# STM32G474 register map
File version: 2.9
CPU: CM4 r0p1, little endian, MPU, FPU, 4 interrupt priority bits
Registers are 32-bit, read-write, reset 0x0 unless marked. A register's access mark holds for its fields unless they carry their own. Offsets are from the block's base; [hi:lo] are bit positions; {n}, {i} and the like mark numbered series; 'fields as' and 'values as' point back to an identical list.

## HRTIM_TIMA — High Resolution Timer: TIMA
Base 0x40016880
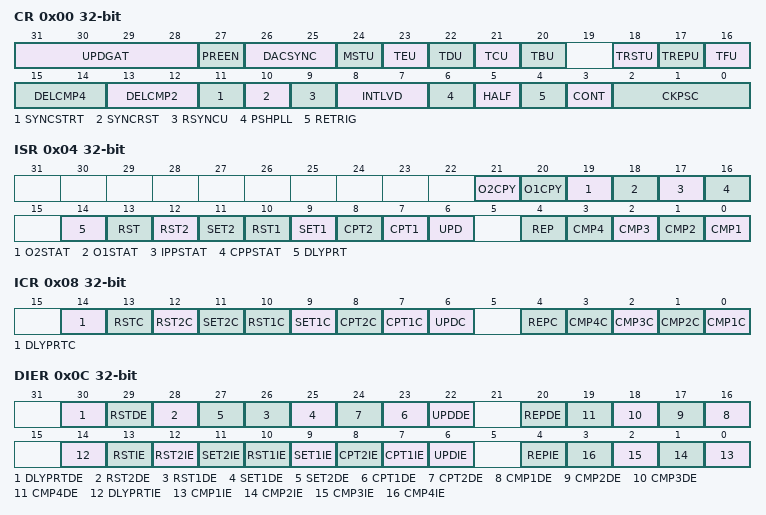
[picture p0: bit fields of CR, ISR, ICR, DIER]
0x00 CR — Timerx Control Register
  [31:28] UPDGAT — Update Gating
    0=Independent (Update occurs independently from the DMA burst transfer); 1=DMABurst (Update occurs when the DMA burst transfer is completed); 2=DMABurst_Update (Update occurs on the update event following DMA burst transfer completion); 3=Input1 (Update occurs on a rising edge of HRTIM update enable input 1); 4=Input2 (Update occurs on a rising edge of HRTIM update enable input 2); 5=Input3 (Update occurs on a rising edge of HRTIM update enable input 3); 6=Input1_Update (Update occurs on the update event following a rising edge of HRTIM update enable input 1); 7=Input2_Update (Update occurs on the update event following a rising edge of HRTIM update enable input 2); 8=Input3_Update (Update occurs on the update event following a rising edge of HRTIM update enable input 3)
  [27] PREEN — Preload enable
    0=Disabled (Preload disabled: the write access is directly done into the active register); 1=Enabled (Preload enabled: the write access is done into the preload register)
  [26:25] DACSYNC — AC Synchronization
    0=Disabled (No DAC trigger generated); 1=Trigger generated on DACSync1; 2=Trigger generated on DACSync2; 3=Trigger generated on DACSync3
  [24] MSTU — Master Timer update
    0=Disabled (Update by master timer disabled); 1=Enabled (Update by master timer enabled)
  [23] TEU
    0=Disabled (Update by timer x disabled); 1=Enabled (Update by timer x enabled)
  [22] TDU
    values as TEU
  [21] TCU
    values as TEU
  [20] TBU
    values as TEU
  [18] TRSTU — Timerx reset update
    0=Disabled (Update by timer x reset/roll-over disabled); 1=Enabled (Update by timer x reset/roll-over enabled)
  [17] TREPU — Timer x Repetition update
    0=Disabled (Update by timer x repetition disabled); 1=Enabled (Update by timer x repetition enabled)
  [16] TFU
    values as TEU
  [15:14] DELCMP4 — Delayed CMP4 mode
    0=Standard (CMP4 register is always active (standard compare mode)); 1=Capture2 (CMP4 is recomputed and is active following a capture 2 event); 2=Capture2_Compare1 (CMP4 is recomputed and is active following a capture 2 event or a Compare 1 match); 3=Capture_Compare3 (CMP4 is recomputed and is active following a capture event or a Compare 3 match)
  [13:12] DELCMP2 — Delayed CMP2 mode
    0=Standard (CMP2 register is always active (standard compare mode)); 1=Capture1 (CMP2 is recomputed and is active following a capture 1 event); 2=Capture1_Compare1 (CMP2 is recomputed and is active following a capture 1 event or a Compare 1 match); 3=Capture1_Compare3 (CMP2 is recomputed and is active following a capture 1 event or a Compare 3 match)
  [11] SYNCSTRT — Synchronization Starts Timer x
    0=Disabled (No effect on the master timer); 1=Start (A synchroniation input event starts the master timer)
  [10] SYNCRST — Synchronization Resets Timer x
    0=Disabled (No effect on the master timer); 1=Reset (A synchroniation input event resets the master timer)
  [9] RSYNCU — Re-Synchronized Update
  [8:7] INTLVD — Interleaved mode
  [6] PSHPLL — Push-Pull mode enable
    0=Disabled (Push-pull mode disabled); 1=Enabled (Push-pull mode enabled)
  [5] HALF — Half mode enable
    0=Disabled (Half mode disabled); 1=Enabled (Half mode enabled)
  [4] RETRIG — Re-triggerable mode
    0=Disabled (The timer is not re-triggerable: a counter reset can be done only if the counter is stopped); 1=Enabled (The timer is retriggerable: a counter reset is done whatever the counter state)
  [3] CONT — Continuous mode
    0=SingleShot (The timer operates in single-shot mode and stops when it reaches the MPER value); 1=Continuous (The timer operates in continuous (free-running) mode and rolls over to zero when it reaches the MPER value)
  [2:0] CKPSC — HRTIM Timer x Clock prescaler
0x04 ISR ro — Timerx Interrupt Status Register
  [21] O2CPY — Output 2 Copy
    0=Inactive (Output is inactive); 1=Active (Output is active)
  [20] O1CPY — Output 1 Copy
    0=Inactive (Output is inactive); 1=Active (Output is active)
  [19] O2STAT — Output 2 State
    0=Inactive (Output was inactive); 1=Active (Output was active)
  [18] O1STAT — Output 1 State
    values as O2STAT
  [17] IPPSTAT — Idle Push Pull Status
    0=Output1Active (Protection occurred when the output 1 was active and output 2 forced inactive); 1=Output2Active (Protection occurred when the output 2 was active and output 1 forced inactive)
  [16] CPPSTAT — Current Push Pull Status
    0=Output1Active (Signal applied on output 1 and output 2 forced inactive); 1=Output2Active (Signal applied on output 2 and output 1 forced inactive)
  [14] DLYPRT — Delayed Protection Flag
    0=Inactive (Not in delayed idle or balanced idle mode); 1=Active (Delayed idle or balanced idle mode entry)
  [13] RST — Reset Interrupt Flag
    0=NoEvent (No TIMx counter reset/roll-over interrupt occurred); 1=Event (TIMx counter reset/roll-over interrupt occurred)
  [12] RST2 — Output 2 Reset Interrupt Flag
    0=NoEvent (No Tx output reset interrupt occurred); 1=Event (Tx output reset interrupt occurred)
  [10] RST1 — Output 1 Reset Interrupt Flag
    values as RST2
  [2n+7] SET{n} (n=1..2) — Output {n} Set Interrupt Flag
    0=NoEvent (No Tx output set interrupt occurred); 1=Event (Tx output set interrupt occurred)
  [n+6] CPT{n} (n=1..2) — Capture{n} Interrupt Flag
    0=NoEvent (No timer x capture reset interrupt occurred); 1=Event (Timer x capture reset interrupt occurred)
  [6] UPD — Update Interrupt Flag
    0=NoEvent (No timer update interrupt occurred); 1=Event (Timer update interrupt occurred)
  [4] REP — Repetition Interrupt Flag
    0=NoEvent (No timer repetition interrupt occurred); 1=Event (Timer repetition interrupt occurred)
  [n-1] CMP{n} (n=1..4) — Compare {n} Interrupt Flag
    0=NoEvent (No compare interrupt occurred); 1=Event (Compare interrupt occurred)
0x08 ICR wo — Timerx Interrupt Clear Register
  [all] fields
    1=Clears associated flag in ISR register
  [14] DLYPRTC write-1-clears — Delayed Protection Flag Clear
  [13] RSTC write-1-clears — Reset Interrupt flag Clear
  [12] RST2C write-1-clears — Output 2 Reset flag Clear
  [10] RST1C write-1-clears — Output 1 Reset flag Clear
  [2n+7] SET{n}C (n=1..2) write-1-clears — Output {n} Set flag Clear
  [n+6] CPT{n}C (n=1..2) write-1-clears — Capture{n} Interrupt flag Clear
  [6] UPDC write-1-clears — Update Interrupt flag Clear
  [4] REPC write-1-clears — Repetition Interrupt flag Clear
  [n-1] CMP{n}C (n=1..4) write-1-clears — Compare {n} Interrupt flag Clear
0x0C DIER — TIMxDIER
  [30] DLYPRTDE
    0=Disabled (DMA request disabled); 1=Enabled (DMA request enabled)
  [29] RSTDE
    values as DLYPRTDE
  [28] RST2DE — RSTx2DE
    values as DLYPRTDE
  [26] RST1DE — RSTx1DE
    values as DLYPRTDE
  [2n+23] SET{n}DE (n=1..2) — Output {n} set DMA request enable
    values as DLYPRTDE
  [n+22] CPT{n}DE (n=1..2) — CPT{n}DE
    values as DLYPRTDE
  [22] UPDDE
    values as DLYPRTDE
  [20] REPDE
    values as DLYPRTDE
  [n+15] CMP{n}DE (n=1..4) — CMP{n}DE
    values as DLYPRTDE
  [14] DLYPRTIE
    0=Disabled (Interrupt disabled); 1=Enabled (Interrupt enabled)
  [13] RSTIE
    values as DLYPRTIE
  [12] RST2IE — RSTx2IE
    values as DLYPRTIE
  [10] RST1IE — RSTx1IE
    values as DLYPRTIE
  [2n+7] SET{n}IE (n=1..2) — Output {n} set interrupt enable
    values as DLYPRTIE
  [n+6] CPT{n}IE (n=1..2) — CPT{n}IE
    values as DLYPRTIE
  [6] UPDIE
    values as DLYPRTIE
  [4] REPIE
    values as DLYPRTIE
  [n-1] CMP{n}IE (n=1..4) — CMP{n}IE
    values as DLYPRTIE
0x10 CNTR — Timerx Counter Register
  [15:0] CNT — Counter value
0x14 PERR reset 0xFFFF — Timerx Period Register
  [15:0] PER — Master Timer Period value
0x18 REPR — Timerx Repetition Register
  [7:0] REP — Master Timer Repetition counter value
0x1C CMP1R — Timerx Compare 1 Register
  [15:0] CMP — Master Timer Compare 1 value
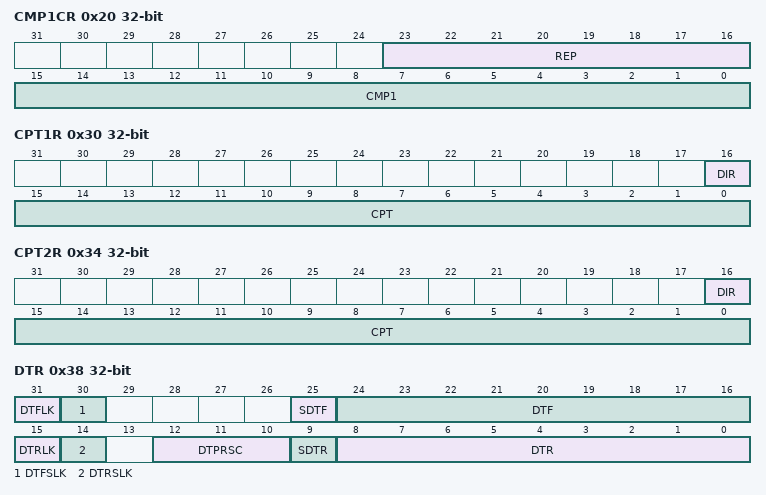
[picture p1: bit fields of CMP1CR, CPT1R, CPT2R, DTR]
0x20 CMP1CR — Timerx Compare 1 Compound Register
  [23:16] REP — Timerx Repetition value (aliased from HRTIM_REPx register)
  [15:0] CMP1 — Timerx Compare 1 value
{0x1C+4i} CMP{i}R (i=2..4) — Timerx Compare {i} Register
  [15:0] CMP — Master Timer Compare 1 value
0x30 CPT1R ro — Timerx Capture 1 Register
  [16] DIR — Timerx Capture 1 Direction status
  [15:0] CPT — Timerx Capture 1 value
0x34 CPT2R ro — Timerx Capture 2 Register
  fields as CPT1R
0x38 DTR — Timerx Deadtime Register
  [31] DTFLK — Deadtime Falling Lock
    0=Unlocked (Deadtime falling value and sign is writable); 1=Locked (Deadtime falling value and sign is read-only)
  [30] DTFSLK — Deadtime Falling Sign Lock
    0=Unlocked (Deadtime falling sign is writable); 1=Locked (Deadtime falling sign is read-only)
  [25] SDTF — Sign Deadtime Falling value
    0=Positive deadtime on falling edge; 1=Negative deadtime on falling edge
  [24:16] DTF — Deadtime Falling value
  [15] DTRLK — Deadtime Rising Lock
    0=Unlocked (Deadtime rising value and sign is writable); 1=Locked (Deadtime rising value and sign is read-only)
  [14] DTRSLK — Deadtime Rising Sign Lock
    0=Unlocked (Deadtime rising sign is writable); 1=Locked (Deadtime rising sign is read-only)
  [12:10] DTPRSC — Deadtime Prescaler
  [9] SDTR — Sign Deadtime Rising value
    0=Positive deadtime on rising edge; 1=Negative deadtime on rising edge
  [8:0] DTR — Deadtime Rising value
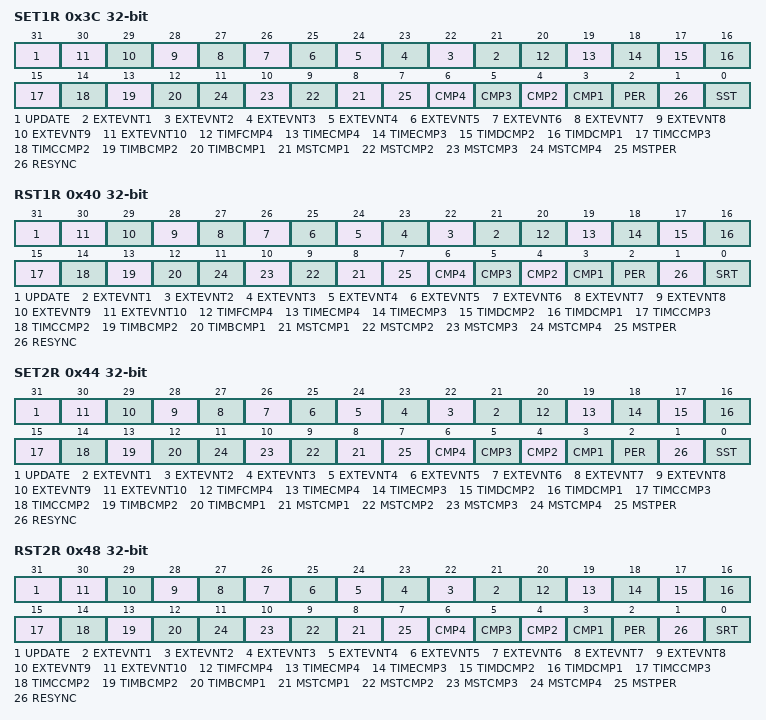
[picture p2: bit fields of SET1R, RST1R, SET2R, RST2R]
0x3C SET1R — Timerx Output1 Set Register
  [31] UPDATE — Registers update (transfer preload to active)
    0=NoEffect (Register update event has no effect); 1=SetActive (Register update event forces the output to its active state)
  [n+20] EXTEVNT{n} (n=1..10) — External Event {n}
    0=NoEffect (External event has no effect); 1=SetActive (External event forces the output to its active state)
  [20] TIMFCMP4 — Timer F Compare 4
    0=NoEffect (Timer event has no effect); 1=SetActive (Timer event forces the output to its active state)
  [19] TIMECMP4 — Timer E Compare 4
    values as TIMFCMP4
  [18] TIMECMP3 — Timer E Compare 3
    values as TIMFCMP4
  [17] TIMDCMP2 — Timer D Compare 2
    values as TIMFCMP4
  [16] TIMDCMP1 — Timer D Compare 1
    values as TIMFCMP4
  [15] TIMCCMP3 — Timer C Compare 3
    values as TIMFCMP4
  [14] TIMCCMP2 — Timer C Compare 2
    values as TIMFCMP4
  [13] TIMBCMP2 — Timer B Compare 2
    values as TIMFCMP4
  [12] TIMBCMP1 — Timer B Compare 1
    values as TIMFCMP4
  [n+7] MSTCMP{n} (n=1..4) — Master Compare {n}
    0=NoEffect (Master timer compare event has no effect); 1=SetActive (Master timer compare event forces the output to its active state)
  [7] MSTPER — Master Period
    0=NoEffect (Master timer counter roll-over/reset has no effect); 1=SetActive (Master timer counter roll-over/reset forces the output to its active state)
  [n+2] CMP{n} (n=1..4) — Timer A compare {n}
    0=NoEffect (Timer compare event has no effect); 1=SetActive (Timer compare event forces the output to its active state)
  [2] PER — Timer A Period
    0=NoEffect (Timer period event has no effect); 1=SetActive (Timer period event forces the output to its active state)
  [1] RESYNC — Timer A resynchronizaton
    0=NoEffect (Timer reset event coming solely from software or SYNC input event has no effect); 1=SetActive (Timer reset event coming solely from software or SYNC input event forces the output to its active state)
  [0] SST — Software Set trigger
    0=NoEffect; 1=SetActive (Force output to its active state)
0x40 RST1R — Timerx Output1 Reset Register
  [31] UPDATE
    0=NoEffect (Register update event has no effect); 1=SetInactive (Register update event forces the output to its inactive state)
  [n+20] EXTEVNT{n} (n=1..10) — EXTEVNT{n}
    0=NoEffect (External event has no effect); 1=SetInactive (External event forces the output to its inactive state)
  [20] TIMFCMP4 — Timer F Compare 4
    values as SET1R.TIMFCMP4
  [19] TIMECMP4 — Timer E Compare 4
    values as SET1R.TIMFCMP4
  [18] TIMECMP3 — Timer E Compare 3
    values as SET1R.TIMFCMP4
  [17] TIMDCMP2 — Timer D Compare 2
    values as SET1R.TIMFCMP4
  [16] TIMDCMP1 — Timer D Compare 1
    values as SET1R.TIMFCMP4
  [15] TIMCCMP3 — Timer C Compare 3
    values as SET1R.TIMFCMP4
  [14] TIMCCMP2 — Timer C Compare 2
    values as SET1R.TIMFCMP4
  [13] TIMBCMP2 — Timer B Compare 2
    values as SET1R.TIMFCMP4
  [12] TIMBCMP1 — Timer B Compare 1
    0=NoEffect (Timer event has no effect); 1=SetInactive (Timer event forces the output to its inactive state)
  [n+7] MSTCMP{n} (n=1..4) — MSTCMP{n}
    0=NoEffect (Master timer compare event has no effect); 1=SetInactive (Master timer compare event forces the output to its inactive state)
  [7] MSTPER
    0=NoEffect (Master timer counter roll-over/reset has no effect); 1=SetInactive (Master timer counter roll-over/reset forces the output to its inactive state)
  [n+2] CMP{n} (n=1..4) — CMP{n}
    0=NoEffect (Timer compare event has no effect); 1=SetInactive (Timer compare event forces the output to its inactive state)
  [2] PER
    0=NoEffect (Timer period event has no effect); 1=SetInactive (Timer period event forces the output to its inactive state)
  [1] RESYNC
    0=NoEffect (Timer reset event coming solely from software or SYNC input event has no effect); 1=SetInactive (Timer reset event coming solely from software or SYNC input event forces the output to its inactive state)
  [0] SRT
    0=NoEffect; 1=SetInactive (Force output to its inactive state)
0x44 SET2R — Timerx Output2 Set Register
  fields as SET1R
0x48 RST2R — Timerx Output2 Reset Register
  fields as RST1R
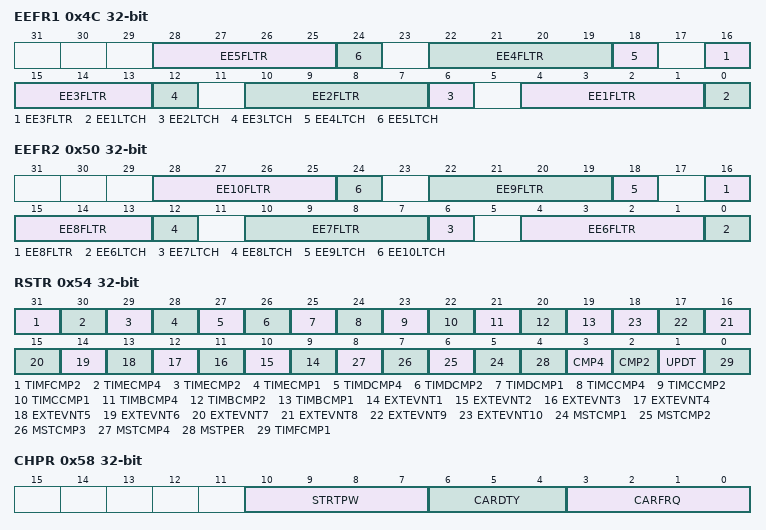
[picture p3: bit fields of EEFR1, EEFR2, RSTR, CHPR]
0x4C EEFR1 — Timerx External Event Filtering Register 1
  [6n-2:6n-5] EE{n}FLTR (n=1..5) — External Event {n} filter
    0=Disabled (No filtering); {v}=BlankResetToCompare{v} (Blanking from counter reset/roll-over to Compare {v}) (v=1..4); {v}=BlankTIMFLTR{v-4} (Blanking from another timing unit: TIMFLTR{v-4} source) (v=5..12); 13=WindowResetToCompare2 (Windowing from counter reset/roll-over to compare 2); 14=WindowResetToCompare3 (Windowing from counter reset/roll-over to compare 3); 15=WindowTIMWIN (Windowing from another timing unit: TIMWIN source)
  [6n-6] EE{n}LTCH (n=1..5) — External Event {n} latch
    0=Disabled (Event is ignored if it happens during a blank, or passed through during a window); 1=Enabled (Event is latched and delayed till the end of the blanking or windowing period)
0x50 EEFR2 — Timerx External Event Filtering Register 2
  [6n-32:6n-35] EE{n}FLTR (n=6..10) — External Event {n} filter
    values as EEFR1.EE1FLTR
  [6n-36] EE{n}LTCH (n=6..10) — External Event {n} latch
    values as EEFR1.EE1LTCH
0x54 RSTR — TimerA Reset Register
  [31] TIMFCMP2 — Timer F Compare 2
    0=NoEffect (Timer Y compare Z event has no effect); 1=ResetCounter (Timer X counter is reset upon timer Y compare Z event)
  [30] TIMECMP4 — Timer E Compare 4
    values as TIMFCMP2
  [29] TIMECMP2 — Timer E Compare 2
    values as TIMFCMP2
  [28] TIMECMP1 — Timer E Compare 1
    values as TIMFCMP2
  [27] TIMDCMP4 — Timer D Compare 4
    values as TIMFCMP2
  [26] TIMDCMP2 — Timer D Compare 2
    values as TIMFCMP2
  [25] TIMDCMP1 — Timer D Compare 1
    values as TIMFCMP2
  [24] TIMCCMP4 — Timer C Compare 4
    values as TIMFCMP2
  [23] TIMCCMP2 — Timer C Compare 2
    values as TIMFCMP2
  [22] TIMCCMP1 — Timer C Compare 1
    values as TIMFCMP2
  [21] TIMBCMP4 — Timer B Compare 4
    values as TIMFCMP2
  [20] TIMBCMP2 — Timer B Compare 2
    values as TIMFCMP2
  [19] TIMBCMP1 — Timer B Compare 1
    values as TIMFCMP2
  [n+8] EXTEVNT{n} (n=1..10) — External Event {n}
    0=NoEffect (External event Z has no effect); 1=ResetCounter (Timer X counter is reset upon external event Z)
  [n+4] MSTCMP{n} (n=1..4) — Master compare {n}
    0=NoEffect (Master timer compare Z event has no effect); 1=ResetCounter (Timer X counter is reset upon master timer compare Z event)
  [4] MSTPER — Master timer Period
    0=NoEffect (Master timer period event has no effect); 1=ResetCounter (Timer X counter is reset upon master timer period event)
  [3] CMP4 — Timer A compare 4 reset
    0=NoEffect (Timer X compare Z event has no effect); 1=ResetCounter (Timer X counter is reset upon timer X compare Z event)
  [2] CMP2 — Timer A compare 2 reset
    values as CMP4
  [1] UPDT — Timer A Update reset
    0=NoEffect (Update event has no effect); 1=ResetCounter (Timer X counter is reset upon update event)
  [0] TIMFCMP1 — Timer A Update reset
    values as TIMFCMP2
0x58 CHPR — Timerx Chopper Register
  [10:7] STRTPW
  [6:4] CARDTY — Timerx chopper duty cycle value
  [3:0] CARFRQ — Timerx carrier frequency value
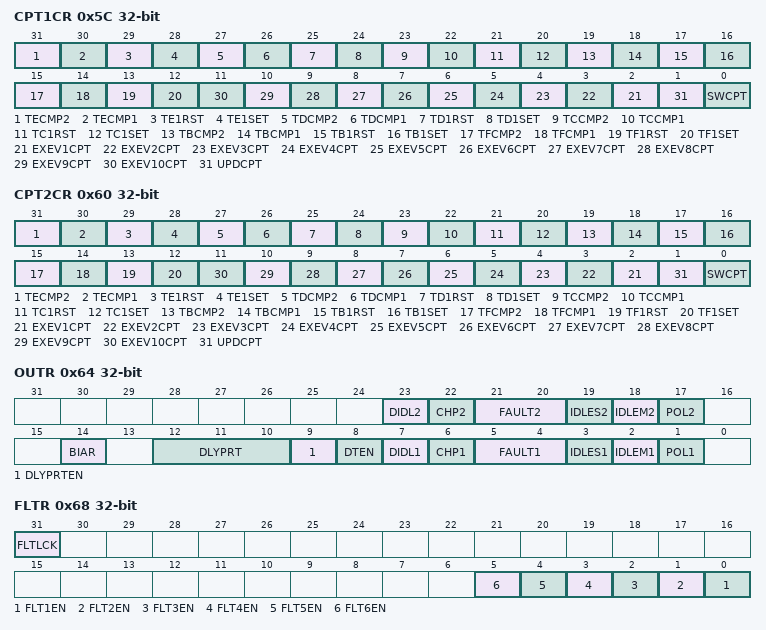
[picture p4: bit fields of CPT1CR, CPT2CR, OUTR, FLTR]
0x5C CPT1CR — Timerx Capture 2 Control Register
  [31] TECMP2 — Timer E Compare 2
    0=NoEffect (Timer X compare Y has no effect); 1=TriggerCapture (Timer X compare Y triggers capture Z)
  [30] TECMP1 — Timer E Compare 1
    values as TECMP2
  [29] TE1RST — Timer E output 1 Reset
    0=NoEffect (Timer X output Y active to inactive transition has no effect); 1=TriggerCapture (Timer X output Y active to inactive transition triggers capture Z)
  [28] TE1SET — Timer E output 1 Set
    0=NoEffect (Timer X output Y inactive to active transition has no effect); 1=TriggerCapture (Timer X output Y inactive to active transition triggers capture Z)
  [27] TDCMP2 — Timer D Compare 2
    values as TECMP2
  [26] TDCMP1 — Timer D Compare 1
    values as TECMP2
  [25] TD1RST — Timer D output 1 Reset
    values as TE1RST
  [24] TD1SET — Timer D output 1 Set
    values as TE1SET
  [23] TCCMP2 — Timer C Compare 2
    values as TECMP2
  [22] TCCMP1 — Timer C Compare 1
    values as TECMP2
  [21] TC1RST — Timer C output 1 Reset
    values as TE1RST
  [20] TC1SET — Timer C output 1 Set
    values as TE1SET
  [19] TBCMP2 — Timer B Compare 2
    values as TECMP2
  [18] TBCMP1 — Timer B Compare 1
    values as TECMP2
  [17] TB1RST — Timer B output 1 Reset
    values as TE1RST
  [16] TB1SET — Timer B output 1 Set
    values as TE1SET
  [15] TFCMP2
    values as TECMP2
  [14] TFCMP1
    values as TECMP2
  [13] TF1RST
    values as TE1RST
  [12] TF1SET
    values as TE1SET
  [n+1] EXEV{n}CPT (n=1..10) — External Event {n} Capture
    0=NoEffect (External event Y has no effect); 1=TriggerCapture (External event Y triggers capture Z)
  [1] UPDCPT — Update Capture
    0=NoEffect (Update event has no effect); 1=TriggerCapture (Update event triggers capture Z)
  [0] SWCPT — Software Capture
    0=NoEffect; 1=TriggerCapture (Force capture Z)
0x60 CPT2CR — CPT2xCR
  fields as CPT1CR
0x64 OUTR — Timerx Output Register
  [23] DIDL2 — Output 2 Deadtime upon burst mode Idle entry
    0=Disabled (The programmed idle state is applied immediately to the output); 1=Enabled (Deadtime (inactive level) is inserted on output before entering the idle mode)
  [22] CHP2 — Output 2 Chopper enable
    0=Disabled (Output signal not altered); 1=Enabled (Output signal is chopped by a carrier signal)
  [21:20] FAULT2 — Output 2 Fault state
    0=Disabled (No action: the output is not affected by the fault input and stays in run mode); 1=SetActive (Output goes to active state after a fault event); 2=SetInactive (Output goes to inactive state after a fault event); 3=SetHighZ (Output goes to high-z state after a fault event)
  [19] IDLES2 — Output 2 Idle State
    0=Inactive (Output idle state is inactive); 1=Active (Output idle state is active)
  [18] IDLEM2 — Output 2 Idle mode
    0=NoEffect (No action: the output is not affected by the burst mode operation); 1=SetIdle (The output is in idle state when requested by the burst mode controller)
  [17] POL2 — Output 2 polarity
    0=ActiveHigh (Positive polarity (output active high)); 1=ActiveLow (Negative polarity (output active low))
  [14] BIAR — Balanced Idle Automatic Resume
  [12:10] DLYPRT — Delayed Protection
    0=Output1_EE6 (Output 1 delayed idle on external event 6); 1=Output2_EE6 (Output 2 delayed idle on external event 6); 2=Output1_2_EE6 (Output 1 and 2 delayed idle on external event 6); 3=Balanced_EE6 (Balanced idle on external event 6); 4=Output1_EE7 (Output 1 delayed idle on external event 7); 5=Output2_EE7 (Output 2 delayed idle on external event 7); 6=Output1_2_EE7 (Output 1 and 2 delayed idle on external event 7); 7=Balanced_EE7 (Balanced idle on external event 7)
  [9] DLYPRTEN — Delayed Protection Enable
    0=Disabled (No action); 1=Enabled (Delayed protection is enabled, as per DLYPRT bits)
  [8] DTEN — Deadtime enable
    0=Disabled (Output 1 and 2 signals are independent); 1=Enabled (Deadtime is inserted between output 1 and output 2)
  [7] DIDL1 — Output 1 Deadtime upon burst mode Idle entry
    values as DIDL2
  [6] CHP1 — Output 1 Chopper enable
    values as CHP2
  [5:4] FAULT1 — Output 1 Fault state
    values as FAULT2
  [3] IDLES1 — Output 1 Idle State
    values as IDLES2
  [2] IDLEM1 — Output 1 Idle mode
    values as IDLEM2
  [1] POL1 — Output 1 polarity
    values as POL2
0x68 FLTR — Timerx Fault Register
  [31] FLTLCK — Fault sources Lock
    0=Unlocked (FLT1EN..FLT5EN bits are read/write); 1=Locked (FLT1EN..FLT5EN bits are read only)
  [n-1] FLT{n}EN (n=1..6) — Fault {n} enable
    0=Ignored (Fault input ignored); 1=Active (Fault input is active and can disable HRTIM outputs)
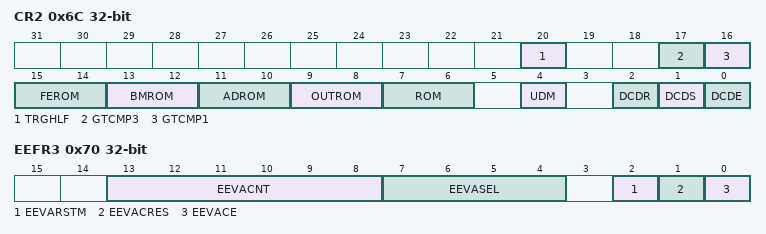
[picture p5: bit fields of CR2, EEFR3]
0x6C CR2 — HRTIM Timerx Control Register 2
  [20] TRGHLF — Triggered-half mode
  [17] GTCMP3 — Greater than Compare 3 PWM mode
  [16] GTCMP1 — Greater than Compare 1 PWM mode
  [15:14] FEROM — Fault and Event Roll-Over Mode
  [13:12] BMROM — Burst Mode Roll-Over Mode
  [11:10] ADROM — ADC Roll-Over Mode
  [9:8] OUTROM — Output Roll-Over Mode
  [7:6] ROM — Roll-Over Mode
  [4] UDM — Up-Down Mode
  [2] DCDR — Dual Channel DAC Reset trigger
  [1] DCDS — Dual Channel DAC Step trigger
  [0] DCDE — Dual Channel DAC trigger enable
0x70 EEFR3 — HRTIM Timerx External Event Filtering Register 3
  [13:8] EEVACNT — External Event A counter
  [7:4] EEVASEL — External Event A Selection
  [2] EEVARSTM — External Event A Reset Mode
  [1] EEVACRES — External Event A Counter Reset
  [0] EEVACE — External Event A Counter Enable
